# A31G21x register map
Vendor: ABOV Semiconductor Co., Ltd.; Series: A31G21x; File version: 1.0
CPU: CM0PLUS r0p1, little endian, no MPU, no FPU, VTOR, 2 interrupt priority bits
Registers are 32-bit, read-write, reset 0x0 unless marked. A register's access mark holds for its fields unless they carry their own. Offsets are from the block's base; [hi:lo] are bit positions; {n}, {i} and the like mark numbered series.

## TOUCH
Base 0x40003600
{0x0+4i} SUM_CH{i} ro (i=0..23) — Touch Sensor Channel 0~23 Sum Register
  [15:0] SUM_CH_DATA — Touch Sensor Channel n Sum or ADC Data
{0x60+4i} SCO{i} (i=0..23) — Touch Sensor Offset Capacitor Selection Register for CH0~23
  [8:0] SCO — Touch Sensor Offset Capacitor Selection 0_0000_0000b: 0pF 0_0000_0001b: 0.1pF 0_0000_0010b: 0.2pF 0_0000_0100b: 0.4pF 0_0000_1000b: 0.8pF 0_0001_0000b: 1.6pF 0_0010_0000b: 3.2pF 0_0100_0000b: 6.4pF 0_1000_0000b: 12.8pF 1_0000_0000b: 25.6pF -- 1_1111_1111b: 51.1pF
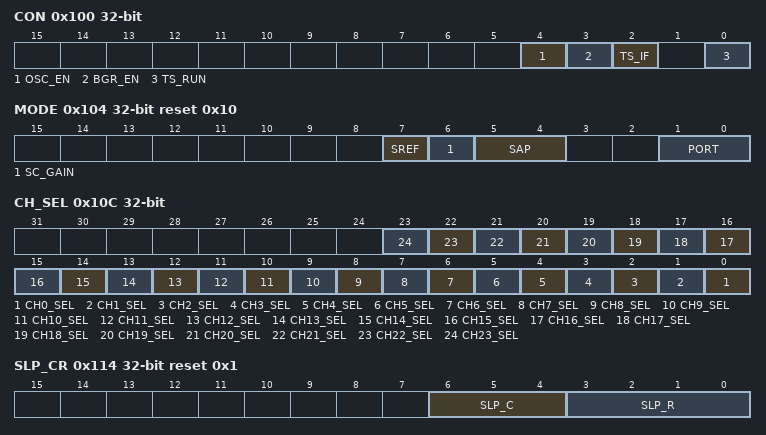
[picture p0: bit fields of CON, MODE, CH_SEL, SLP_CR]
0x100 CON — Touch Sensor Control Register
  [4] OSC_EN wo — Oscillator Enable
  [3] BGR_EN — Band Gap Reference Enable
  [2] TS_IF — Touch Sensor Interrupt Flag
  [0] TS_RUN — Touch Sensor Enable
0x104 MODE reset 0x10 — Touch Sensor Mode Register
  [7] SREF — External Reference Offset Enable 0: Disable 1: Enable
  [6] SC_GAIN — Gain Calibration Capacitor Enable 0: Gain Calibration Capacitor Disable (Default) 1: Gain Calibration Capacitor Enable
  [5:4] SAP — Touch Sensor Selection 01: Touch Sensor mode Select (Default) 10: ADC. The result of ADC is stored only at SUM_CH0 register
  [1:0] PORT — Port Configuration During Inactive Status 00: Input Floating 01: Output Low 10: Output High
0x108 SUM_CNT reset 0x1 — Touch Sensor Sum Repeat Count Register
  [7:0] TS_SUM_CNT — Touch Sensor Sum Repeat Count
0x10C CH_SEL — Touch Sensor Channel Selection Register
  [n] CH{n}_SEL (n=0..23) — Touch Sensor Channel Selection Register 0: Disable (Default) 1: Enable Touch Key
0x114 SLP_CR reset 0x1 — Touch Sensor Low Pass Filter Control Register
  [6:4] SLP_C — Capacitor Trimming for Input Low Pass Filter 000: 0pF 001: 4pF 010: 8pF 011: 12pF 100: 16pF 101: 20pF 110: 24pF 111: 28pF
  [3:0] SLP_R — Resistor Trimming for Input Low Pass Filter 0000: Channel open 0001: 0k 0010: 5k 0100: 10k 1000: 20k 1110: 2.8k 0110: 3.3k 1010: 4.0k 1100: 6.7k
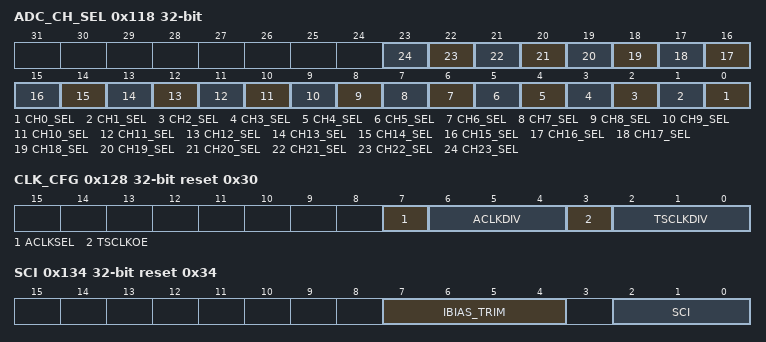
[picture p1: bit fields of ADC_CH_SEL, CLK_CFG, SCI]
0x118 ADC_CH_SEL — ADC Channel Selection Register
  [n] CH{n}_SEL (n=0..23) — ADC Channel Selection 0: Disable (Default) 1: Enable
0x11C INTEG_CNT reset 0x32 — Touch Sensor Sensing Integration Count Register
  [7:0] TS_INTEG_CNT — Touch Sensor Sensing Integration Count
0x120 FREQ_NUM reset 0xFF — Touch Sensor Frequency Number Register
  [7:0] TS_FREQ_NUM — Touch Sensor Frequency Number
0x124 FREQ_DEL — Touch Sensor Frequency Delta Register
  [7:0] TS_FREQ_DEL
0x128 CLK_CFG reset 0x30 — Touch Sensor Clock Configuration Register
  [7] ACLKSEL — ADC Clock Source Select 0: Touch Sensor Clock 1: System MCU Clock
  [6:4] ACLKDIV — ADC Clock Divider 000: OSCsys / 1 (48MHz) 001: OSCsys / 2 (24MHz) 010: OSCsys / 4 (12MHz) 011: OSCsys / 8 (6MHz, default) 100: OSCsys / 16 101: OSCsys / 32 110: OSCsys / 64 111: OSCsys / 128
  [3] TSCLKOE — Divided Touch Sensor Clock Output Enable 0: Clock Output Disable (Default) 1: Clock Output Enable
  [2:0] TSCLKDIV — Touch Sensor Clock Divider 000: OSCts / 1 (27MHz) 001: OSCts / 2 010: OSCts / 4 011: OSCts / 8 100: OSCts / 16 101: OSCts / 32 110: OSCts / 64 111: OSCts / 128
0x12C TRIM_OSC reset 0xB8 — Touch Sensor RING Oscillator Trimming Selection Register
  [7:0] TRIM_OSC — Touch Sensor RING Oscillator Trimming Selection 0x00: 44MHz (maximum) 0xB8: 27MHz (default) 0xFF: 6MHz (minimum)
0x130 TRIM_A_OSC reset 0xFF — Touch Sensor RING Oscillator Trimming for ADC Register
  [7:0] TRIM_A_OSC — Touch Sensor RING Oscillator Trimming for ADC 0x00: 44MHz (maximum) 0xB8: 27MHz (default) 0xFF: 6MHz (minimum)
0x134 SCI reset 0x34 — Touch Sensor Input Capacitor Selection Register
  [7:4] IBIAS_TRIM — BGR Current Bias Control
  [2:0] SCI — Touch Sensor Input Capacitor Selection 000: 1.2pF 001: 2.4pF 010: 3.6pF 011: 4.8pF 100: 6.0pF 101: 7.2pF 110: 8.4pF 111: 9.6pF
0x138 SCC reset 0x4 — Touch Sensor Conversion Capacitor Selection Register
  [2:0] SCC — Touch Sensor Conversion Capacitor Selection 000: 2.4pF 001: 4.8pF 010: 7.2pF 011: 9.6pF 100: 12.0pF 101: 14.4pF 110: 16.8pF 111: 19.2pF
0x13C SVREF reset 0x4 — Touch Sensor VREF Resistor Selection Register
  [3:0] SVREF — Touch Sensor VREF Resistor Selection 0000: Open 0001: 2.5k 0010: 5k 0100: 10k 1000: 20k 1111: 1.3k
0x140 TAR reset 0x20 — Touch Sensor Integration AMP Reset Register
  [7:0] TAR
0x144 TRST reset 0x3 — Touch Sensor Reset time of Sensing Register
  [7:0] TRST — Touch Sensor Reset time of Sensing
0x148 TDRV reset 0x3 — Touch Sensor Sample time of Sensing Register
  [7:0] TDRV — Touch Sensor Driving time of Sensing
0x14C TINT reset 0x14 — Touch Sensor Integration time of Sensing Register
  [7:0] TINT — Touch Sensor Integration time of Sensing
0x150 TD reset 0x20 — Touch Sensor Differential AMP Sampling Register
  [7:0] TD — Touch Sensor Differential AMP Sampling
0x154 TWR reset 0x10 — Touch Sensor Wait time Register
  [7:0] TWR — Touch Sensor Wait Time
0x158 TLED — LED stable time Register
  [7:0] TLED — LED stable Time
